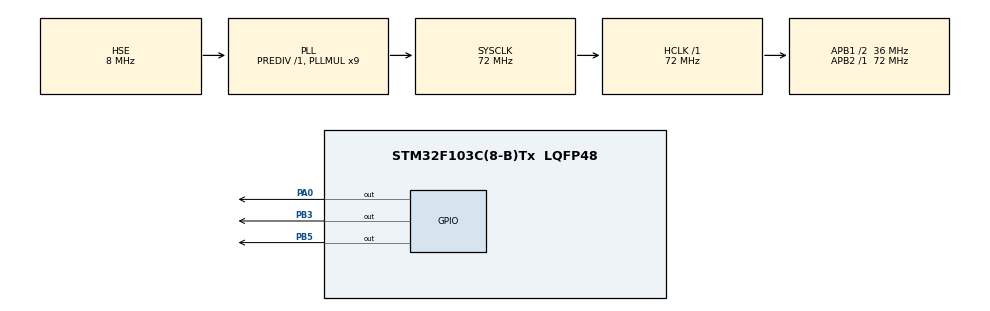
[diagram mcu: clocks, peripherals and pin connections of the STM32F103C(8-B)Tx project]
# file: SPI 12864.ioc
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Mcu.Family=STM32F1
Mcu.Name=STM32F103C(8-B)Tx
Mcu.Package=LQFP48
NVIC.PriorityGroup=NVIC_PRIORITYGROUP_4
PA0-WKUP.GPIO_PuPd=GPIO_PULLUP
PA0-WKUP.PinState=GPIO_PIN_SET
PA0-WKUP.Signal=GPIO_Output
PA13.Mode=Serial_Wire
PA13.Signal=SYS_JTMS-SWDIO
PA14.Mode=Serial_Wire
PA14.Signal=SYS_JTCK-SWCLK
PB3.GPIO_Speed=GPIO_SPEED_FREQ_HIGH
PB3.Signal=GPIO_Output
PB5.GPIO_Speed=GPIO_SPEED_FREQ_HIGH
PB5.Signal=GPIO_Output
PD0-OSC_IN.Mode=HSE-External-Oscillator
PD0-OSC_IN.Signal=RCC_OSC_IN
PD1-OSC_OUT.Mode=HSE-External-Oscillator
PD1-OSC_OUT.Signal=RCC_OSC_OUT
ProjectManager.HeapSize=0x200
ProjectManager.StackSize=0x400
ProjectManager.TargetToolchain=EWARM V7
RCC.AHBFreq_Value=72000000
RCC.APB1CLKDivider=RCC_HCLK_DIV2
RCC.APB1Freq_Value=36000000
RCC.APB1TimFreq_Value=72000000
RCC.APB2Freq_Value=72000000
RCC.APB2TimFreq_Value=72000000
RCC.HCLKFreq_Value=72000000
RCC.PLLMUL=RCC_PLL_MUL9
RCC.PLLSourceVirtual=RCC_PLLSOURCE_HSE
RCC.SYSCLKFreq_VALUE=72000000
RCC.SYSCLKSource=RCC_SYSCLKSOURCE_PLLCLK
RCC.USBFreq_Value=72000000
board=custom

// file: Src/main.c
/**
  ******************************************************************************
  * @file           : main.c
  * @brief          : Main program body
  ******************************************************************************
  ** This notice applies to any and all portions of this file
  * that are not between comment pairs USER CODE BEGIN and
  * USER CODE END. Other portions of this file, whether
  * inserted by the user or by software development tools
  * are owned by their respective copyright owners.
  *
  * COPYRIGHT(c) 2019 STMicroelectronics
  *
  * Redistribution and use in source and binary forms, with or without modification,
  * are permitted provided that the following conditions are met:
  *   1. Redistributions of source code must retain the above copyright notice,
  *      this list of conditions and the following disclaimer.
  *   2. Redistributions in binary form must reproduce the above copyright notice,
  *      this list of conditions and the following disclaimer in the documentation
  *      and/or other materials provided with the distribution.
  *   3. Neither the name of STMicroelectronics nor the names of its contributors
  *      may be used to endorse or promote products derived from this software
  *      without specific prior written permission.
  *
  * THIS SOFTWARE IS PROVIDED BY THE COPYRIGHT HOLDERS AND CONTRIBUTORS "AS IS"
  * AND ANY EXPRESS OR IMPLIED WARRANTIES, INCLUDING, BUT NOT LIMITED TO, THE
  * IMPLIED WARRANTIES OF MERCHANTABILITY AND FITNESS FOR A PARTICULAR PURPOSE ARE
  * DISCLAIMED. IN NO EVENT SHALL THE COPYRIGHT HOLDER OR CONTRIBUTORS BE LIABLE
  * FOR ANY DIRECT, INDIRECT, INCIDENTAL, SPECIAL, EXEMPLARY, OR CONSEQUENTIAL
  * DAMAGES (INCLUDING, BUT NOT LIMITED TO, PROCUREMENT OF SUBSTITUTE GOODS OR
  * SERVICES; LOSS OF USE, DATA, OR PROFITS; OR BUSINESS INTERRUPTION) HOWEVER
  * CAUSED AND ON ANY THEORY OF LIABILITY, WHETHER IN CONTRACT, STRICT LIABILITY,
  * OR TORT (INCLUDING NEGLIGENCE OR OTHERWISE) ARISING IN ANY WAY OUT OF THE USE
  * OF THIS SOFTWARE, EVEN IF ADVISED OF THE POSSIBILITY OF SUCH DAMAGE.
  *
  ******************************************************************************
  */
#include "main.h"
#include "stm32f1xx_hal.h"
#include "gpio.h"

/* USER CODE BEGIN PV */
/* Private variables ---------------------------------------------------------*/

/* USER CODE END PV */

void SystemClock_Config(void);

/* USER CODE BEGIN PFP */
/* Private function prototypes -----------------------------------------------*/

/* USER CODE END PFP */

/* USER CODE BEGIN 0 */
#define  SCL_SET      HAL_GPIO_WritePin(GPIOB, GPIO_PIN_3, GPIO_PIN_SET)
#define  SDA_SET      HAL_GPIO_WritePin(GPIOB, GPIO_PIN_5, GPIO_PIN_SET)
#define  SCL_RESET    HAL_GPIO_WritePin(GPIOB, GPIO_PIN_3, GPIO_PIN_RESET)
#define  SDA_RESET    HAL_GPIO_WritePin(GPIOB, GPIO_PIN_5, GPIO_PIN_RESET)
void Delay(uint32_t count)//用于产生400KHzIIC信号所需要的延时
{
 // count=count*5;
  while (count--);
}
/**************************实现函数********************************************
*函数原型:		void IIC_Send_Byte(u8 txd)
*功　　能:	    IIC发送一个字节
*******************************************************************************/
void IIC_Send_Byte(uint8_t txd)
{
    uint8_t t;
    uint8_t t_temp;
   // SDA_OUT();
    SCL_RESET;//拉低时钟开始数据传输
    for(t=0;t<8;t++)
    {
      t_temp=txd&0x80;
      if((t_temp>>7)==0)
      SDA_RESET;
      else if((t_temp>>7)==1)
      SDA_SET;
        txd<<=1;

		Delay(15);
		SCL_SET;
		Delay(15);
		SCL_RESET;
		Delay(15);
    }
}

void LCD_wr(uint8_t lcd_com,uint8_t lcd_data)                                         //写入LCD数据或命令
{
        uint8_t lcd_data_msb,lcd_data_lsb;
        uint8_t cmd=0xf8;
        uint8_t data=0xfa;
        lcd_data_msb=0xf0&lcd_data;
       lcd_data_lsb= (lcd_data<< 4) & 0xf0;
        //lcd_data_lsb=(0x0f&lcd_data)<<4;
        if(lcd_com==0)                                        //写命令
        {
          //      while(SPI_I2S_GetFlagStatus(SPI1, SPI_I2S_FLAG_TXE)==RESET);        //等待 SPI1 发送缓冲空
          IIC_Send_Byte(cmd);
          //  HAL_SPI_Transmit_DMA(&hspi1,    &cmd,1);                        // SPI1 发送数据--命令指令--
        }
        if(lcd_com==1)                                        //写数据
        {
           //     while(SPI_I2S_GetFlagStatus(SPI1, SPI_I2S_FLAG_TXE)==RESET);                //等待 SPI1 发送缓冲空
          IIC_Send_Byte(data);
       //     HAL_SPI_Transmit_DMA(&hspi1, &data,1);                    //SPI1 发送数据--数据指令--
        }
       // HAL_Delay(100);
       // while(SPI_I2S_GetFlagStatus(SPI1, SPI_I2S_FLAG_TXE)==RESET);                //等待 SPI1 接收数据完毕
        IIC_Send_Byte(lcd_data_msb);
        IIC_Send_Byte(lcd_data_lsb);
      //  HAL_SPI_Transmit_DMA(&hspi1, &lcd_data_msb,1);                   //SPI1 发送高4位数据
   //     HAL_Delay(100);
    //    while(SPI_I2S_GetFlagStatus(SPI1, SPI_I2S_FLAG_TXE)==RESET);                //Wait for SPI1 Tx buffer empty
     //   HAL_SPI_Transmit_DMA(&hspi1, &lcd_data_lsb,1);            // SPI1 发送低4位数据
        HAL_Delay(100);
}
void initlcd(void)                          //LCD初始化
{
  LCD_wr(0,0x30);                  //30---基本指令动作
  HAL_Delay (10);
  LCD_wr(0,0x01);                  //清屏，地址指针指向00H
  HAL_Delay (10);
  LCD_wr(0,0x06);                  //光标的移动方向
  HAL_Delay (10);
  LCD_wr(0,0x0c);                  //开显示，关游标
  HAL_Delay (10);
}

//========================================================
 /*
        1.总共分为上下两个屏幕,其中第0->31行和第32->63行的行地址相同

        (上 0->31)第一个屏幕的首地址(0x80,0x80) -> ... -> (0x80,0x87)
                                   ....
                                  (0xa0,0x80) -> ... -> (0xa0,0x87)
        (下 32->63)第二个屏幕的首地址(0x80,0x88) -> ... -> (0x80,0x90)
                                    ...
                                 (0xa0,0x88) -> ... -> (0xa0,0x90)

        2.每个地址就是控制 一行16个小点,发送两次数据分别控制前8点和后8个点,
            例写入的01010101 01010101来控制屏幕的点 , 1显示 0不显示

        3.先写入行地址,后写入列地址,连续写列地址会自动增加
        */

        //进行清屏操作 LCD12864_Clear_Screen(0xFF)全亮
            //LCD12864_Clear_Screen(0xFF)全灭
        void LCD12864_Clear_Screen(unsigned char value)
        {
            unsigned char i,j;

            LCD_wr(0,0x34);
            LCD_wr(0,0x36);

            for(i=0;i<64;i++){
                    if(i<32){
                    LCD_wr(0,0x80+i);
                    LCD_wr(0,0x80);
                    }else {
                    LCD_wr(0,0x80+(i-32));
                    LCD_wr(0,0x88);
                    }

                    for(j=0;j<16;j++)
                        LCD_wr(1,value);
            }
        }
//显示非中文字符 和 中文字符都差不多,因为自带汉字库,只是注意写汉字的时候要连续写!
// 注意这里的坐标变了,一定要注意!!!
    /*
    实际坐标:
        0x80 -> 0x87
        0x90 -> 0x97
        0x88 -> 0x8f
        0x98 -> 0x9f

        //这个坐标我们自己规定的,再换算成上面的实际坐标就可以了
        指出坐标(1,1) -> (1,8)
                (4,1) -> (4,8)
        再指出需要显示的字符
        */
        unsigned char addresses[] = {0x80,0x90,0x88,0x98};
        void LCD12864_Display_Char(unsigned char x,unsigned char y,unsigned char dat){

                LCD_wr(0,0x30);
                LCD_wr(0,0x06);

                //写入地址
                LCD_wr(0,addresses[x-1]+(y-1));

                //写入数据
                LCD_wr(1,dat);

        }

        //显示汉字
        void LCD12864_Display_Chars(unsigned char x,unsigned char y,unsigned char *dat){

                LCD_wr(0,0x30);
                LCD_wr(0,0x06);

                //写入地址
                LCD_wr(0,addresses[x-1]+(y-1));

                //写入数据
                while(*dat != '\0'){
                    LCD_wr(1,*dat);
                    dat++;
                }
        }
/* USER CODE END 0 */

int main(void)
{

  /* MCU Configuration----------------------------------------------------------*/

  /* Reset of all peripherals, Initializes the Flash interface and the Systick. */
  HAL_Init();

  /* Configure the system clock */
  SystemClock_Config();

  /* Initialize all configured peripherals */
  MX_GPIO_Init();
  /* USER CODE BEGIN 2 */
  HAL_GPIO_WritePin(GPIOA, GPIO_PIN_0, GPIO_PIN_SET);
initlcd();

unsigned char *datas ="LCD液晶显示";
  /* USER CODE END 2 */

  /* Infinite loop */
  /* USER CODE BEGIN WHILE */
  while (1)
  {
    LCD12864_Display_Char(1,2,'A');
        LCD12864_Display_Chars(2,1,datas);
  /* USER CODE END WHILE */

  }

}

void SystemClock_Config(void)
{

  RCC_OscInitTypeDef RCC_OscInitStruct;
  RCC_ClkInitTypeDef RCC_ClkInitStruct;

    /**Initializes the CPU, AHB and APB busses clocks
    */
  RCC_OscInitStruct.OscillatorType = RCC_OSCILLATORTYPE_HSE;
  RCC_OscInitStruct.HSEState = RCC_HSE_ON;
  RCC_OscInitStruct.HSEPredivValue = RCC_HSE_PREDIV_DIV1;
  RCC_OscInitStruct.HSIState = RCC_HSI_ON;
  RCC_OscInitStruct.PLL.PLLState = RCC_PLL_ON;
  RCC_OscInitStruct.PLL.PLLSource = RCC_PLLSOURCE_HSE;
  RCC_OscInitStruct.PLL.PLLMUL = RCC_PLL_MUL9;
  if (HAL_RCC_OscConfig(&RCC_OscInitStruct) != HAL_OK)
  {
    _Error_Handler(__FILE__, __LINE__);
  }

    /**Initializes the CPU, AHB and APB busses clocks
    */
  RCC_ClkInitStruct.ClockType = RCC_CLOCKTYPE_HCLK|RCC_CLOCKTYPE_SYSCLK
                              |RCC_CLOCKTYPE_PCLK1|RCC_CLOCKTYPE_PCLK2;
  RCC_ClkInitStruct.SYSCLKSource = RCC_SYSCLKSOURCE_PLLCLK;
  RCC_ClkInitStruct.AHBCLKDivider = RCC_SYSCLK_DIV1;
  RCC_ClkInitStruct.APB1CLKDivider = RCC_HCLK_DIV2;
  RCC_ClkInitStruct.APB2CLKDivider = RCC_HCLK_DIV1;

  if (HAL_RCC_ClockConfig(&RCC_ClkInitStruct, FLASH_LATENCY_2) != HAL_OK)
  {
    _Error_Handler(__FILE__, __LINE__);
  }

    /**Configure the Systick interrupt time
    */
  HAL_SYSTICK_Config(HAL_RCC_GetHCLKFreq()/1000);

    /**Configure the Systick
    */
  HAL_SYSTICK_CLKSourceConfig(SYSTICK_CLKSOURCE_HCLK);

  /* SysTick_IRQn interrupt configuration */
  HAL_NVIC_SetPriority(SysTick_IRQn, 0, 0);
}

void _Error_Handler(char *file, int line)
{
  while(1)
  {
  }
}

/************************ (C) COPYRIGHT STMicroelectronics *****END OF FILE****/
